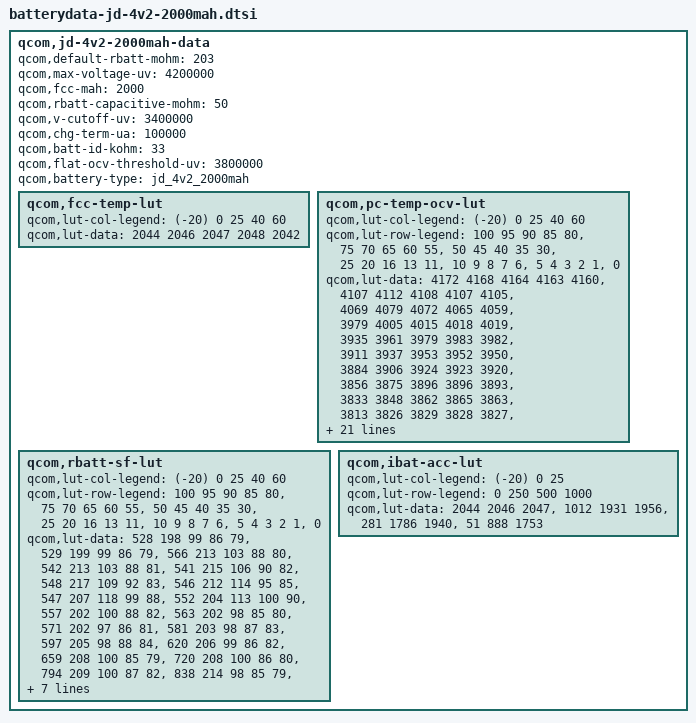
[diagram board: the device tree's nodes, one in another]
qcom,jd-4v2-2000mah-data {
	qcom,default-rbatt-mohm = <203>;
	qcom,max-voltage-uv = <4200000>;
	qcom,fcc-mah = <2000>;
	qcom,rbatt-capacitive-mohm = <50>;
	qcom,v-cutoff-uv = <3400000>;
	qcom,chg-term-ua = <100000>;
	qcom,batt-id-kohm = <33>;
	qcom,flat-ocv-threshold-uv = <3800000>;
	qcom,battery-type = "jd_4v2_2000mah";
	
	qcom,fcc-temp-lut {
		qcom,lut-col-legend = <(-20) 0 25 40 60>;
		qcom,lut-data = <2044 2046 2047 2048 2042>;
    };
	qcom,pc-temp-ocv-lut {
		qcom,lut-col-legend = <(-20) 0 25 40 60>;
		qcom,lut-row-legend = <100 95 90 85 80>,
				<75 70 65 60 55>,
				<50 45 40 35 30>,
				<25 20 16 13 11>,
				<10 9 8 7 6>,
				<5 4 3 2 1>,
				<0>;
		qcom,lut-data = <4172 4168 4164 4163 4160>,
				<4107 4112 4108 4107 4105>,
				<4069 4079 4072 4065 4059>,
				<3979 4005 4015 4018 4019>,
				<3935 3961 3979 3983 3982>,
				<3911 3937 3953 3952 3950>,
				<3884 3906 3924 3923 3920>,
				<3856 3875 3896 3896 3893>,
				<3833 3848 3862 3865 3863>,
				<3813 3826 3829 3828 3827>,
				<3797 3808 3808 3807 3806>,
				<3786 3792 3793 3793 3791>,
				<3777 3782 3782 3782 3779>,
				<3768 3774 3774 3772 3769>,
				<3757 3766 3766 3760 3752>,
				<3744 3753 3753 3743 3730>,
				<3727 3735 3733 3724 3711>,
				<3709 3719 3712 3703 3691>,
				<3690 3708 3692 3683 3672>,
				<3675 3702 3688 3680 3669>,
				<3664 3698 3686 3679 3668>,
				<3651 3692 3685 3677 3667>,
				<3634 3685 3682 3674 3664>,
				<3612 3672 3675 3666 3657>,
				<3583 3646 3655 3643 3632>,
				<3547 3605 3614 3601 3591>,
				<3487 3551 3560 3547 3541>,
				<3408 3479 3490 3479 3479>,
				<3301 3378 3400 3389 3399>,
				<3139 3230 3259 3232 3275>,
				<2772 2750 2750 2750 3000>;
    };
	qcom,rbatt-sf-lut {
		qcom,lut-col-legend = <(-20) 0 25 40 60>;
		qcom,lut-row-legend = <100 95 90 85 80>,
				<75 70 65 60 55>,
				<50 45 40 35 30>,
				<25 20 16 13 11>,
				<10 9 8 7 6>,
				<5 4 3 2 1>,
				<0>;
		qcom,lut-data = <528 198 99 86 79>,
				<529 199 99 86 79>,
				<566 213 103 88 80>,
				<542 213 103 88 81>,
				<541 215 106 90 82>,
				<548 217 109 92 83>,
				<546 212 114 95 85>,
				<547 207 118 99 88>,
				<552 204 113 100 90>,
				<557 202 100 88 82>,
				<563 202 98 85 80>,
				<571 202 97 86 81>,
				<581 203 98 87 83>,
				<597 205 98 88 84>,
				<620 206 99 86 82>,
				<659 208 100 85 79>,
				<720 208 100 86 80>,
				<794 209 100 87 82>,
				<838 214 98 85 79>,
				<790 216 98 86 80>,
				<830 219 98 86 82>,
				<874 224 100 88 84>,
				<931 231 102 91 87>,
				<987 235 105 92 88>,
				<1048 236 105 90 83>,
				<1113 241 102 89 84>,
				<1318 256 105 92 86>,
				<1915 284 112 100 93>,
				<6691 383 138 119 104>,
				<44065 14374 1595 497 130>,
				<156206 114267 98296 89512 139585>;
    };
	qcom,ibat-acc-lut {
		qcom,lut-col-legend = <(-20) 0 25>;
		qcom,lut-row-legend = <0 250 500 1000>;
		qcom,lut-data = <2044 2046 2047>,
				<1012 1931 1956>,
				<281 1786 1940>,
				<51 888 1753>;
	};
};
